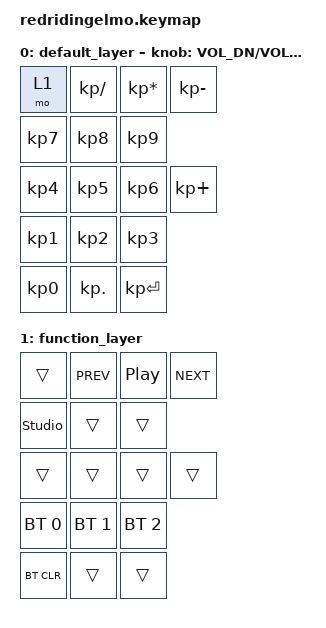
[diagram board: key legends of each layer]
#include <behaviors.dtsi>
#include <dt-bindings/zmk/keys.h>
#include <dt-bindings/zmk/bt.h>

/ {
    keymap {
        compatible = "zmk,keymap";

        default_layer {
            bindings = <
                &mo 1           &kp KP_SLASH    &kp KP_ASTERISK &kp KP_MINUS
                &kp KP_NUMBER_7 &kp KP_NUMBER_8 &kp KP_NUMBER_9
                &kp KP_NUMBER_4 &kp KP_NUMBER_5 &kp KP_NUMBER_6 &kp KP_PLUS
                &kp KP_NUMBER_1 &kp KP_NUMBER_2 &kp KP_NUMBER_3
                &kp KP_NUMBER_0 &kp KP_DOT      &kp KP_ENTER 
            >;
            sensor-bindings = <&inc_dec_kp C_VOL_DN C_VOL_UP>;
        };
        function_layer {
            bindings = <
                &trans            &kp C_PREV   &kp C_PLAY_PAUSE &kp C_NEXT
                &studio_unlock    &trans       &trans
                &trans &trans     &trans       &trans
                &bt BT_SEL 0      &bt BT_SEL 1 &bt BT_SEL 2 
                &bt BT_CLR        &trans       &trans
            >;
        };
    };
};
